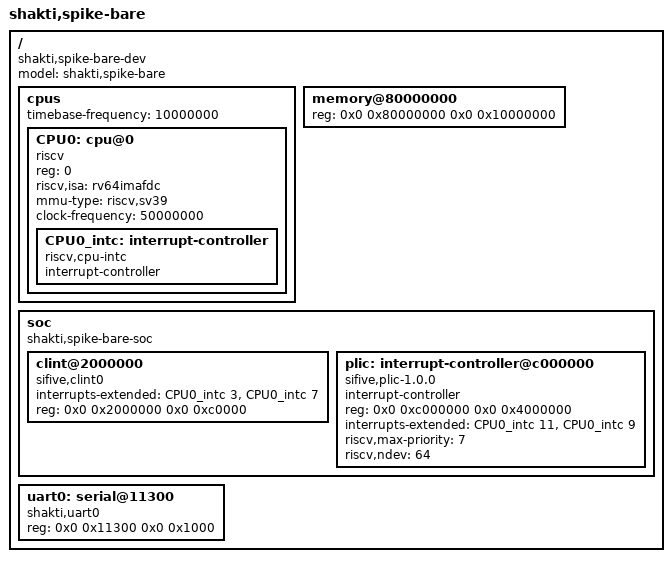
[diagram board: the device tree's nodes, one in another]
/ {
#address-cells = <2>;
#size-cells = <2>;
  compatible = "shakti,spike-bare-dev";
  model = "shakti,spike-bare";
  cpus {
#address-cells = <1>;
#size-cells = <0>;
    timebase-frequency = <10000000>;
CPU0: cpu@0 {
        device_type = "cpu";
        reg = <0>;
        status = "okay";
        compatible = "riscv";
        riscv,isa = "rv64imafdc";
        mmu-type = "riscv,sv39";
        clock-frequency = <50000000>;
CPU0_intc: interrupt-controller {
             #address-cells = <0>;
	           #interrupt-cells = <1>;
             interrupt-controller;
             compatible = "riscv,cpu-intc";
           };
      };
  };
  memory@80000000 {
    device_type = "memory";
    reg = <0x0 0x80000000 0x0 0x10000000 >;
  };
  soc {
    #address-cells = <2>;
    #size-cells = <2>;
    compatible = "shakti,spike-bare-soc", "simple-bus";
    ranges;
    clint@2000000 {
      compatible = "sifive,clint0";
      interrupts-extended = <&CPU0_intc 3 &CPU0_intc 7 >;
      reg = <0x0 0x2000000 0x0 0xc0000>;
    };
    plic: interrupt-controller@c000000 {
      #address-cells = <0>;
      #interrupt-cells = <2>;
      compatible = "sifive,plic-1.0.0";
      interrupt-controller;
      reg = <0x0 0xc000000 0x0 0x4000000>;
      interrupts-extended = <&CPU0_intc 11 &CPU0_intc 9>; //11 as to mention MACHINE MODE for CPU or 9 for SUPERVISOR MODE for CPU...
      reg-names = "control";
      riscv,max-priority = <7>;
      riscv,ndev = <64>;
    };
  };

uart0: serial@11300 {
         compatible = "shakti,uart0";
         reg= < 0x0 0x11300 0x0 0x1000>;
  };
};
